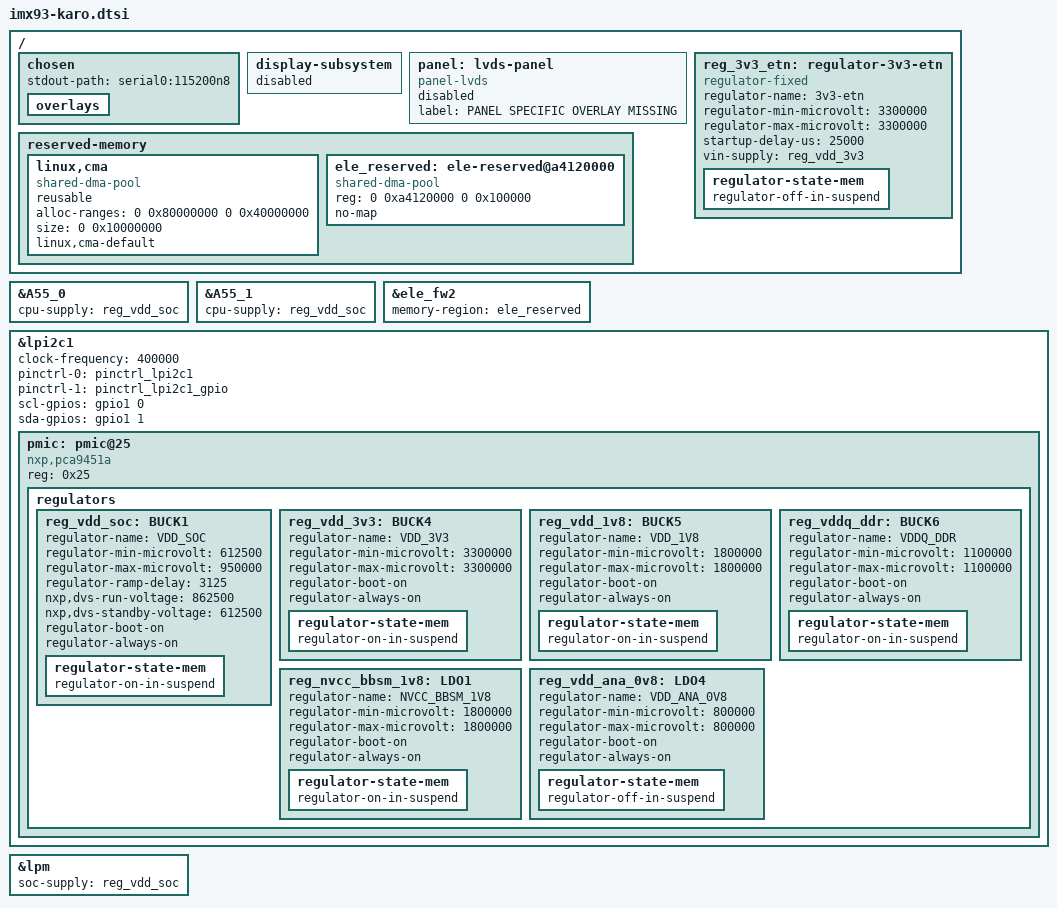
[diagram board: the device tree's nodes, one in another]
// SPDX-License-Identifier: (GPL-2.0+ OR MIT)
/*
 * Copyright 2023 Lothar Waßmann <LW@KARO-electronics.de>
 * Copyright 2023 Markus Bauer <MB@KARO-electronics.de>
 */

/dts-v1/;

#include "imx93.dtsi"

/ {
	chosen {
		stdout-path = "serial0:115200n8";

		overlays {
		};
	};

	display-subsystem {
		status = "disabled";
	};

	panel: lvds-panel {
		compatible = "panel-lvds";
		label = "PANEL SPECIFIC OVERLAY MISSING";
		status = "disabled";
	};

	reg_3v3_etn: regulator-3v3-etn {
		compatible = "regulator-fixed";
		regulator-name = "3v3-etn";
		regulator-min-microvolt = <3300000>;
		regulator-max-microvolt = <3300000>;
		startup-delay-us = <25000>;
		vin-supply = <&reg_vdd_3v3>;

		regulator-state-mem {
			regulator-off-in-suspend;
		};
	};

	reserved-memory {
		#address-cells = <2>;
		#size-cells = <2>;
		ranges;

		linux,cma {
			compatible = "shared-dma-pool";
			reusable;
			alloc-ranges = <0 0x80000000 0 0x40000000>;
			size = <0 0x10000000>;
			linux,cma-default;
		};

		ele_reserved: ele-reserved@a4120000 {
			compatible = "shared-dma-pool";
			reg = <0 0xa4120000 0 0x100000>;
			no-map;
		};
	};
};

&A55_0 {
	cpu-supply = <&reg_vdd_soc>;
};

&A55_1 {
	cpu-supply = <&reg_vdd_soc>;
};

&ele_fw2 {
	memory-region = <&ele_reserved>;
};

&lpi2c1 {
	clock-frequency = <400000>;
	pinctrl-names = "default", "gpio";
	pinctrl-0 = <&pinctrl_lpi2c1>;
	pinctrl-1 = <&pinctrl_lpi2c1_gpio>;
	scl-gpios = <&gpio1 0 (GPIO_ACTIVE_HIGH | GPIO_OPEN_DRAIN)>;
	sda-gpios = <&gpio1 1 (GPIO_ACTIVE_HIGH | GPIO_OPEN_DRAIN)>;
	status = "okay";

	pmic: pmic@25 {
		compatible = "nxp,pca9451a";
		reg = <0x25>;

		regulators {
			reg_vdd_soc: BUCK1 {
				regulator-name = "VDD_SOC";
				regulator-min-microvolt = <612500>;
				regulator-max-microvolt = <950000>;
				regulator-ramp-delay = <3125>;
				nxp,dvs-run-voltage = <862500>;
				nxp,dvs-standby-voltage = <612500>;
				regulator-boot-on;
				regulator-always-on;

				regulator-state-mem {
					regulator-on-in-suspend;
				};
			};

			reg_vdd_3v3: BUCK4 {
				regulator-name = "VDD_3V3";
				regulator-min-microvolt = <3300000>;
				regulator-max-microvolt = <3300000>;
				regulator-boot-on;
				regulator-always-on;

				regulator-state-mem {
					regulator-on-in-suspend;
				};
			};

			reg_vdd_1v8: BUCK5 {
				regulator-name = "VDD_1V8";
				regulator-min-microvolt = <1800000>;
				regulator-max-microvolt = <1800000>;
				regulator-boot-on;
				regulator-always-on;

				regulator-state-mem {
					regulator-on-in-suspend;
				};
			};

			reg_vddq_ddr: BUCK6 {
				/* VDDQ_DDR (1.1V) for LPDDR4 SDRAM */
				regulator-name = "VDDQ_DDR";
				regulator-min-microvolt = <1100000>;
				regulator-max-microvolt = <1100000>;
				regulator-boot-on;
				regulator-always-on;

				regulator-state-mem {
					regulator-on-in-suspend;
				};
			};

			reg_nvcc_bbsm_1v8: LDO1 {
				regulator-name = "NVCC_BBSM_1V8";
				regulator-min-microvolt = <1800000>;
				regulator-max-microvolt = <1800000>;
				regulator-boot-on;
				regulator-always-on;

				regulator-state-mem {
					regulator-on-in-suspend;
				};
			};

			reg_vdd_ana_0v8: LDO4 {
				regulator-name = "VDD_ANA_0V8";
				regulator-min-microvolt = <800000>;
				regulator-max-microvolt = <800000>;
				regulator-boot-on;
				regulator-always-on;

				regulator-state-mem {
					regulator-off-in-suspend;
				};
			};
		};
	};
};

&lpm {
	soc-supply = <&reg_vdd_soc>;
	status = "okay";
};
